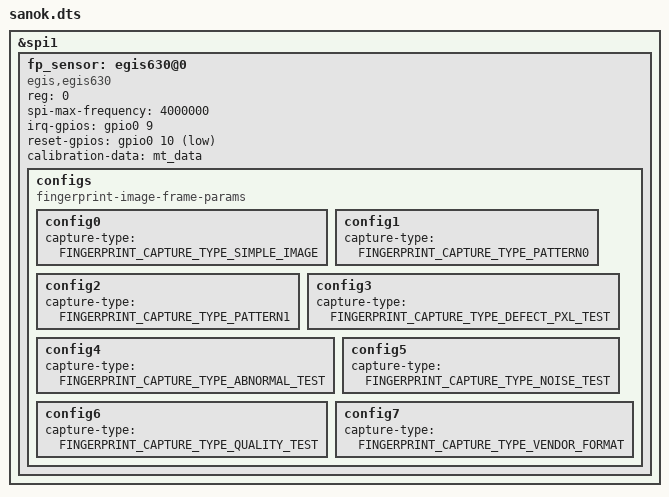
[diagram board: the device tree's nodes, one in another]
/* Copyright 2025 The ChromiumOS Authors.
 * Use of this source code is governed by a BSD-style license that can be
 * found in the LICENSE file.
 */

#include "common.dtsi"
#include "btn_ign.dtsi"

#define EGIS630_TEST_IMAGE_PROPS \
	width = <80>; \
	height = <64>; \
	bits-per-pixel = <16>; \
	frame-size = <10240>; \
	image-data-offset-bytes = <0>; \
	v4l2-pixel-format = "V4L2_PIX_FMT_GREY";

#define EGIS630_IMAGE_COLLECTION_PROPS \
	width = <80>; \
	height = <64>; \
	bits-per-pixel = <8>; \
	frame-size = <26200>; \
	image-data-offset-bytes = <0>; \
	v4l2-pixel-format = "V4L2_PIX_FMT_GREY";

&spi1 {
	fp_sensor: egis630@0 {
		compatible = "egis,egis630";
		reg = <0>;
		spi-max-frequency = <4000000>;

		configs {
			compatible = "fingerprint-image-frame-params";
			config0 {
				EGIS630_IMAGE_COLLECTION_PROPS
				capture-type = "FINGERPRINT_CAPTURE_TYPE_SIMPLE_IMAGE";
			};
			config1 {
				EGIS630_TEST_IMAGE_PROPS
				capture-type = "FINGERPRINT_CAPTURE_TYPE_PATTERN0";
			};
			config2 {
				EGIS630_TEST_IMAGE_PROPS
				capture-type = "FINGERPRINT_CAPTURE_TYPE_PATTERN1";
			};
			config3 {
				EGIS630_TEST_IMAGE_PROPS
				capture-type = "FINGERPRINT_CAPTURE_TYPE_DEFECT_PXL_TEST";
			};
			config4 {
				EGIS630_TEST_IMAGE_PROPS
				capture-type = "FINGERPRINT_CAPTURE_TYPE_ABNORMAL_TEST";
			};
			config5 {
				EGIS630_TEST_IMAGE_PROPS
				capture-type = "FINGERPRINT_CAPTURE_TYPE_NOISE_TEST";
			};
			config6 {
				EGIS630_TEST_IMAGE_PROPS
				capture-type = "FINGERPRINT_CAPTURE_TYPE_QUALITY_TEST";
			};
			config7 {
				EGIS630_IMAGE_COLLECTION_PROPS
				capture-type = "FINGERPRINT_CAPTURE_TYPE_VENDOR_FORMAT";
			};
		};

		irq-gpios = <&gpio0 9 GPIO_ACTIVE_HIGH>;
		reset-gpios = <&gpio0 10 GPIO_ACTIVE_LOW>;
		calibration-data = <&mt_data>;
	};
};
